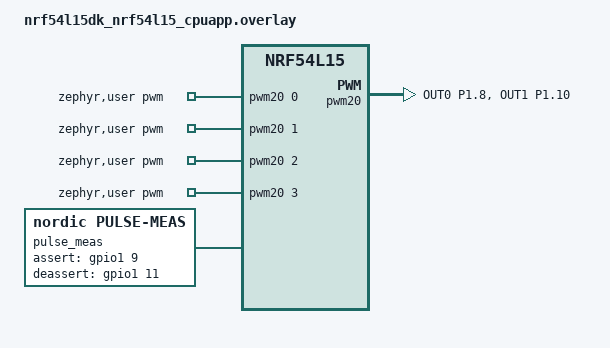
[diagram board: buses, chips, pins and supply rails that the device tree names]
/*
 * Copyright (c) 2026 Nordic Semiconductor ASA
 *
 * SPDX-License-Identifier: LicenseRef-Nordic-5-Clause
 */

/ {
	zephyr,user {
		pwms = <&pwm20 0 1600000 PWM_POLARITY_NORMAL>,
		       <&pwm20 1 1600000 PWM_POLARITY_NORMAL>,
		       <&pwm20 2 1600000 PWM_POLARITY_NORMAL>,
		       <&pwm20 3 1600000 PWM_POLARITY_NORMAL>;
	};

	pulse_meas: pulse-meas {
		compatible = "nordic,pulse-meas";
		status = "okay";
		timer-instance = <&timer20>;
		assert-gpios = <&gpio1 9 GPIO_ACTIVE_HIGH>;
		deassert-gpios = <&gpio1 11 GPIO_ACTIVE_HIGH>;
	};
};

&pinctrl {
	pwm20_default: pwm20_default {
		group1 {
			psels = <NRF_PSEL(PWM_OUT0, 1, 8)>,
				<NRF_PSEL(PWM_OUT1, 1, 10)>;
		};
	};

	pwm20_sleep: pwm20_sleep {
		group1 {
			psels = <NRF_PSEL(PWM_OUT0, 1, 8)>,
				<NRF_PSEL(PWM_OUT1, 1, 10)>;
			low-power-enable;
		};
	};
};

tester_pwm: &pwm20 {
	status = "okay";
	pinctrl-0 = <&pwm20_default>;
	pinctrl-1 = <&pwm20_sleep>;
	pinctrl-names = "default", "sleep";
};

&timer20 {
	status = "reserved";
};

&gpio1 {
	status = "okay";
};
